VERSION ""

BU_: CH DIPF DIPR ETH FC HVI HVS PARTY SDCV VEH VIRT
BO_ 962 VCLEFT_switchStatus: 8 VEH
 SG_ VCLEFT_frontBuckleSwitch m0: 48|2@1+ (1,0) [0|3] "" gtw
 SG_ VCLEFT_btnWindowSwPackUpLF m0: 32|1@1+ (1,0) [0|1] "" gtw
 SG_ VCLEFT_frontSeatTrackBack m0: 8|2@1+ (1,0) [0|3] "" gtw
 SG_ VCLEFT_btnWindowSwPackAutoDownLF m0: 35|1@1+ (1,0) [0|1] "" gtw
 SG_ VCLEFT_btnWindowSwPackDownRR m0: 46|1@1+ (1,0) [0|1] "" gtw
 SG_ VCLEFT_btnWindowSwPackAutoUpRR m0: 45|1@1+ (1,0) [0|1] "" gtw
 SG_ VCLEFT_btnWindowSwPackAutoDownRR m0: 47|1@1+ (1,0) [0|1] "" gtw
 SG_ VCLEFT_rightMirrorTilt m0: 5|3@1+ (1,0) [0|4] "" vcright
 SG_ VCLEFT_btnWindowSwPackUpRR m0: 44|1@1+ (1,0) [0|1] "" gtw
 SG_ VCLEFT_frontOccupancySwitch m0: 50|2@1+ (1,0) [0|3] "" gtw
 SG_ VCLEFT_swcRightTiltLeft m1: 8|2@1+ (1,0) [0|3] "" das
 SG_ VCLEFT_rearRightOccupancySwitch m0: 58|2@1+ (1,0) [0|3] "" gtw
 SG_ VCLEFT_btnWindowSwPackDownLF m0: 34|1@1+ (1,0) [0|1] "" gtw
 SG_ VCLEFT_btnWindowSwPackAutoUpLF m0: 33|1@1+ (1,0) [0|1] "" gtw
 SG_ VCLEFT_swcLeftTiltRight m1: 3|2@1+ (1,0) [0|3] "" das
 SG_ VCLEFT_frontSeatBackrestForward m0: 22|2@1+ (1,0) [0|3] "" gtw
 SG_ VCLEFT_swcRightTiltRight m1: 10|2@1+ (1,0) [0|3] "" das
 SG_ VCLEFT_swcLeftScrollTicks m1: 16|6@1- (1,0) [-32|31] "" das
 SG_ VCLEFT_btnWindowUpLR m1: 32|1@1+ (1,0) [0|1] "" gtw
 SG_ VCLEFT_btnWindowAutoDownLR m1: 35|1@1+ (1,0) [0|1] "" gtw
 SG_ VCLEFT_btnWindowSwPackDownRF m0: 42|1@1+ (1,0) [0|1] "" gtw
 SG_ VCLEFT_btnWindowSwPackAutoUpRF m0: 41|1@1+ (1,0) [0|1] "" gtw
 SG_ VCLEFT_frontSeatLumbarIn m0: 28|2@1+ (1,0) [0|3] "" gtw
 SG_ VCLEFT_frontSeatLiftUp m0: 18|2@1+ (1,0) [0|3] "" gtw
 SG_ VCLEFT_btnWindowSwPackDownLR m0: 38|1@1+ (1,0) [0|1] "" gtw
 SG_ VCLEFT_btnWindowSwPackAutoUpLR m0: 37|1@1+ (1,0) [0|1] "" gtw
 SG_ VCLEFT_frontSeatLumbarDown m0: 24|2@1+ (1,0) [0|3] "" gtw
 SG_ VCLEFT_driverPresent m0: 4|1@1+ (1,0) [0|1] "" das
 SG_ VCLEFT_frontSeatTiltDown m0: 12|2@1+ (1,0) [0|3] "" gtw
 SG_ VCLEFT_frontSeatTrackForward m0: 10|2@1+ (1,0) [0|3] "" gtw
 SG_ VCLEFT_rearLeftBuckleSwitch m0: 52|2@1+ (1,0) [0|3] "" gtw
 SG_ VCLEFT_hazardButtonPressed m0: 3|1@1+ (1,0) [0|1] "" gtw
 SG_ VCLEFT_swcRightScrollTicks m1: 24|6@1- (1,0) [-32|31] "" das
 SG_ VCLEFT_swcRightPressed m1: 12|2@1+ (1,0) [0|3] "" das
 SG_ VCLEFT_frontSeatLumbarOut m0: 30|2@1+ (1,0) [0|3] "" gtw
 SG_ VCLEFT_brakePressed m0: 60|1@1+ (1,0) [0|1] "" di
 SG_ VCLEFT_swcLeftTiltLeft m1: 14|2@1+ (1,0) [0|3] "" das
 SG_ VCLEFT_swcLeftPressed m1: 5|2@1+ (1,0) [0|3] "" das
 SG_ VCLEFT_btnWindowSwPackUpLR m0: 36|1@1+ (1,0) [0|1] "" gtw
 SG_ VCLEFT_frontSeatTiltUp m0: 14|2@1+ (1,0) [0|3] "" gtw
 SG_ VCLEFT_rearLeftOccupancySwitch m0: 56|2@1+ (1,0) [0|3] "" gtw
 SG_ VCLEFT_frontSeatBackrestBack m0: 20|2@1+ (1,0) [0|3] "" gtw
 SG_ VCLEFT_btnWindowSwPackAutoDownLR m0: 39|1@1+ (1,0) [0|1] "" gtw
 SG_ VCLEFT_rearCenterOccupancySwitch m0: 54|2@1+ (1,0) [0|3] "" gtw
 SG_ VCLEFT_frontSeatLumbarUp m0: 26|2@1+ (1,0) [0|3] "" gtw
 SG_ VCLEFT_frontSeatLiftDown m0: 16|2@1+ (1,0) [0|3] "" gtw
 SG_ VCLEFT_hornSwitchPressed m0: 2|1@1+ (1,0) [0|1] "" app
 SG_ VCLEFT_btnWindowSwPackUpRF m0: 40|1@1+ (1,0) [0|1] "" gtw
 SG_ VCLEFT_btnWindowAutoUpLR m1: 33|1@1+ (1,0) [0|1] "" gtw
 SG_ VCLEFT_btnWindowSwPackAutoDownRF m0: 43|1@1+ (1,0) [0|1] "" gtw
 SG_ VCLEFT_switchStatusIndex M: 0|2@1+ (1,0) [0|2] "" X
 SG_ VCLEFT_btnWindowDownLR m1: 34|1@1+ (1,0) [0|1] "" gtw
 SG_ VCLEFT_rearHVACButtonPressed m0: 61|1@1+ (1,0) [0|1] "" gtw

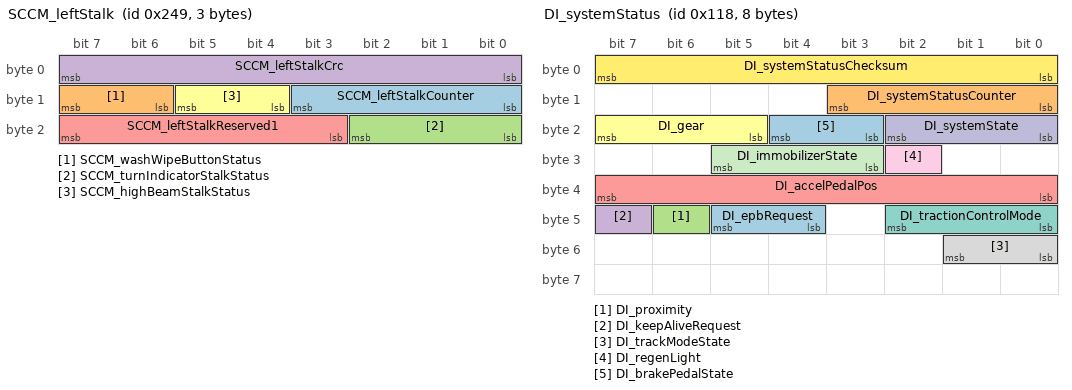
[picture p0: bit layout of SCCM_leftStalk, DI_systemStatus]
BO_ 585 SCCM_leftStalk: 3 VEH
 SG_ SCCM_leftStalkCounter : 8|4@1+ (1,0) [0|15] "" X
 SG_ SCCM_washWipeButtonStatus : 14|2@1+ (1,0) [0|3] "" das
 SG_ SCCM_turnIndicatorStalkStatus : 16|3@1+ (1,0) [0|5] "" das
 SG_ SCCM_leftStalkCrc : 0|8@1+ (1,0) [0|255] "" X
 SG_ SCCM_leftStalkReserved1 : 19|5@1+ (1,0) [0|31] "" X
 SG_ SCCM_highBeamStalkStatus : 12|2@1+ (1,0) [0|3] "" das

BO_ 280 DI_systemStatus: 8 VEH
 SG_ DI_epbRequest : 44|2@1+ (1,0) [0|2] "" epbl
 SG_ DI_systemStatusCounter : 8|4@1+ (1,0) [0|15] "" X
 SG_ DI_proximity : 46|1@1+ (1,0) [0|1] "" bms
 SG_ DI_keepAliveRequest : 47|1@1+ (1,0) [0|1] "" bms
 SG_ DI_accelPedalPos : 32|8@1+ (0.4,0) [0|100] "%" vcfront
 SG_ DI_gear : 21|3@1+ (1,0) [0|7] "" gtw
 SG_ DI_tractionControlMode : 40|3@1+ (1,0) [0|5] "" X
 SG_ DI_trackModeState : 48|2@1+ (1,0) [0|2] "" gtw
 SG_ DI_regenLight : 26|1@1+ (1,0) [0|1] "" vcleft
 SG_ DI_systemState : 16|3@1+ (1,0) [0|5] "" epbl
 SG_ DI_immobilizerState : 27|3@1+ (1,0) [0|6] "" X
 SG_ DI_systemStatusChecksum : 0|8@1+ (1,0) [0|255] "" X
 SG_ DI_brakePedalState : 19|2@1+ (1,0) [0|2] "" vcleft

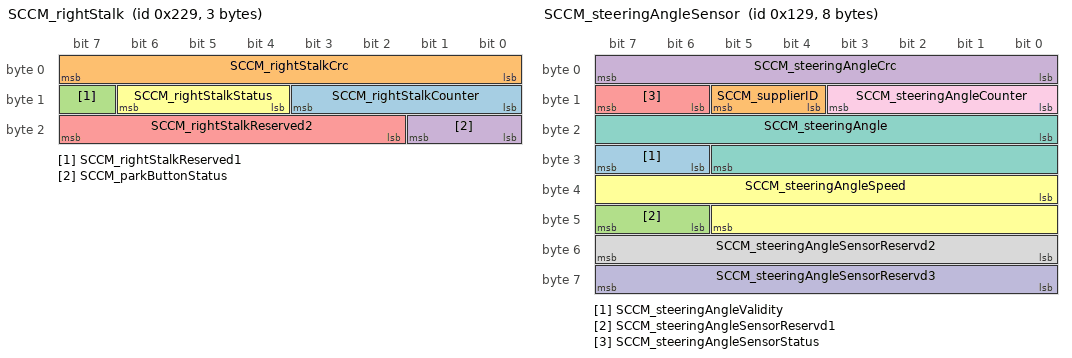
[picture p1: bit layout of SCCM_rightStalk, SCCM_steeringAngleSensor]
BO_ 553 SCCM_rightStalk: 3 VEH
 SG_ SCCM_rightStalkCounter : 8|4@1+ (1,0) [0|15] "" X
 SG_ SCCM_rightStalkCrc : 0|8@1+ (1,0) [0|255] "" X
 SG_ SCCM_rightStalkReserved1 : 15|1@1+ (1,0) [0|1] "" X
 SG_ SCCM_parkButtonStatus : 16|2@1+ (1,0) [0|3] "" das
 SG_ SCCM_rightStalkReserved2 : 18|6@1+ (1,0) [0|63] "" X
 SG_ SCCM_rightStalkStatus : 12|3@1+ (1,0) [0|6] "" das

BO_ 297 SCCM_steeringAngleSensor: 8 VEH
 SG_ SCCM_steeringAngleValidity : 30|2@1+ (1,0) [0|3] "" gtw
 SG_ SCCM_supplierID : 12|2@1+ (1,0) [0|3] "" gtw
 SG_ SCCM_steeringAngleSensorReservd1 : 46|2@1+ (1,0) [0|3] "" X
 SG_ SCCM_steeringAngleCrc : 0|8@1+ (1,0) [0|255] "" gtw
 SG_ SCCM_steeringAngleSensorStatus : 14|2@1+ (1,0) [0|3] "" aps
 SG_ SCCM_steeringAngleSpeed : 32|14@1+ (0.5,-4096) [-4096|4095.5] "deg/s" das
 SG_ SCCM_steeringAngle : 16|14@1+ (0.1,-819.2) [-819.2|819] "deg" aps
 SG_ SCCM_steeringAngleSensorReservd2 : 48|8@1+ (1,0) [0|255] "" X
 SG_ SCCM_steeringAngleCounter : 8|4@1+ (1,0) [0|15] "" gtw
 SG_ SCCM_steeringAngleSensorReservd3 : 56|8@1+ (1,0) [0|255] "" X

BO_ 568 STW_ACTN_RQ: 8 STW
 SG_ SpdCtrlLvr_Stat : 0|6@1+ (1,0) [0|0] "" NEO
 SG_ VSL_Enbl_Rq : 6|1@1+ (1,0) [0|0] "" NEO
 SG_ SpdCtrlLvrStat_Inv : 7|1@1+ (1,0) [0|0] "" NEO
 SG_ DTR_Dist_Rq : 8|8@1+ (1,0) [0|200] "" NEO
 SG_ TurnIndLvr_Stat : 16|2@1+ (1,0) [0|0] "" NEO
 SG_ HiBmLvr_Stat : 18|2@1+ (1,0) [0|0] "" NEO
 SG_ WprWashSw_Psd : 20|2@1+ (1,0) [0|0] "" NEO
 SG_ WprWash_R_Sw_Posn_V2 : 22|2@1+ (1,0) [0|0] "" NEO
 SG_ StW_Lvr_Stat : 24|3@1+ (1,0) [0|0] "" NEO
 SG_ StW_Cond_Flt : 27|1@1+ (1,0) [0|0] "" NEO
 SG_ StW_Cond_Psd : 28|2@1+ (1,0) [0|0] "" NEO
 SG_ HrnSw_Psd : 30|2@1+ (1,0) [0|0] "" NEO
 SG_ StW_Sw00_Psd : 32|1@1+ (1,0) [0|0] "" NEO
 SG_ StW_Sw01_Psd : 33|1@1+ (1,0) [0|0] "" NEO
 SG_ StW_Sw02_Psd : 34|1@1+ (1,0) [0|0] "" NEO
 SG_ StW_Sw03_Psd : 35|1@1+ (1,0) [0|0] "" NEO
 SG_ StW_Sw04_Psd : 36|1@1+ (1,0) [0|0] "" NEO
 SG_ StW_Sw05_Psd : 37|1@1+ (1,0) [0|0] "" NEO
 SG_ StW_Sw06_Psd : 38|1@1+ (1,0) [0|0] "" NEO
 SG_ StW_Sw07_Psd : 39|1@1+ (1,0) [0|0] "" NEO
 SG_ StW_Sw08_Psd : 40|1@1+ (1,0) [0|0] "" NEO
 SG_ StW_Sw09_Psd : 41|1@1+ (1,0) [0|0] "" NEO
 SG_ StW_Sw10_Psd : 42|1@1+ (1,0) [0|0] "" NEO
 SG_ StW_Sw11_Psd : 43|1@1+ (1,0) [0|0] "" NEO
 SG_ StW_Sw12_Psd : 44|1@1+ (1,0) [0|0] "" NEO
 SG_ StW_Sw13_Psd : 45|1@1+ (1,0) [0|0] "" NEO
 SG_ StW_Sw14_Psd : 46|1@1+ (1,0) [0|0] "" NEO
 SG_ StW_Sw15_Psd : 47|1@1+ (1,0) [0|0] "" NEO
 SG_ WprSw6Posn : 48|3@1+ (1,0) [0|0] "" NEO
 SG_ MC_STW_ACTN_RQ : 52|4@1+ (1,0) [0|15] "" NEO
 SG_ CRC_STW_ACTN_RQ : 56|8@1+ (1,0) [0|0] "" NEO

BO_ 737 VCFRONT_status: 8 VEH
 SG_ VCFRONT_statusIndex M : 0|3@1+ (1,0) [0|6] ""  Receiver
 SG_ VCFRONT_12VARailStable m5 : 5|1@1+ (1,0) [0|1] ""  Receiver
 SG_ VCFRONT_12VBRailStable m5 : 6|1@1+ (1,0) [0|1] ""  Receiver
 SG_ VCFRONT_12VOverchargeCounter m4 : 16|4@1+ (1,0) [0|15] ""  Receiver
 SG_ VCFRONT_5VARailStable m5 : 3|1@1+ (1,0) [0|1] ""  Receiver
 SG_ VCFRONT_5VBRailStable m5 : 4|1@1+ (1,0) [0|1] ""  Receiver
 SG_ VCFRONT_AS8510Voltage m5 : 28|12@1+ (0.00544368,0) [0|22.2864] "V"  Receiver
 SG_ VCFRONT_ChargePumpVoltageStable m5 : 9|1@1+ (1,0) [0|1] ""  Receiver
 SG_ VCFRONT_HSDInitCompleteU13 m5 : 11|1@1+ (1,0) [0|1] ""  Receiver
 SG_ VCFRONT_HSDInitCompleteU16 m5 : 12|1@1+ (1,0) [0|1] ""  Receiver
 SG_ VCFRONT_IBSFault m4 : 15|1@1+ (1,0) [0|1] ""  Receiver
 SG_ VCFRONT_PCSMia m4 : 14|1@1+ (1,0) [0|1] ""  Receiver
 SG_ VCFRONT_PEResetLineState m5 : 10|1@1+ (1,0) [0|1] ""  Receiver
 SG_ VCFRONT_airCompressorStatus m0 : 25|3@1+ (1,0) [0|7] ""  Receiver
 SG_ VCFRONT_anyClosureOpen m0 : 49|1@1+ (1,0) [0|1] ""  Receiver
 SG_ VCFRONT_anyDoorOpen m0 : 50|1@1+ (1,0) [0|1] ""  Receiver
 SG_ VCFRONT_batterySMState m1 : 16|4@1+ (1,0) [0|8] ""  Receiver
 SG_ VCFRONT_chargeNeeded m4 : 13|1@1+ (1,0) [0|1] ""  Receiver
 SG_ VCFRONT_chillerDemandActive m3 : 26|1@1+ (1,0) [0|1] ""  Receiver
 SG_ VCFRONT_compPerfRecoveryLimited m3 : 27|1@1+ (1,0) [0|1] ""  Receiver
 SG_ VCFRONT_coolantFillRoutineStatus m3 : 50|2@1+ (1,0) [0|3] ""  Receiver
 SG_ VCFRONT_crashDetectedType m0 : 20|2@1+ (1,0) [0|3] ""  Receiver
 SG_ VCFRONT_crashState m0 : 22|2@1+ (1,0) [0|3] ""  Receiver
 SG_ VCFRONT_crashUnlockOverrideSet m0 : 24|1@1+ (1,0) [0|1] ""  Receiver
 SG_ VCFRONT_epasWakeLine m1 : 4|1@1+ (1,0) [0|1] ""  Receiver
 SG_ VCFRONT_freezeEvapITerm m3 : 24|1@1+ (1,0) [0|1] ""  Receiver
 SG_ VCFRONT_frunkAccessPost m0 : 62|1@1+ (1,0) [0|1] ""  Receiver
 SG_ VCFRONT_frunkInteriorRelSwitch m0 : 48|1@1+ (1,0) [0|1] ""  Receiver
 SG_ VCFRONT_frunkLatchStatus m0 : 3|4@1+ (1,0) [0|8] ""  Receiver
 SG_ VCFRONT_frunkLatchType m0 : 58|2@1+ (1,0) [0|2] ""  Receiver
 SG_ VCFRONT_hasLowRefrigerant m3 : 29|1@1+ (1,0) [0|1] ""  Receiver
 SG_ VCFRONT_headlampLeftFanStatus m0 : 60|1@1+ (1,0) [0|1] ""  Receiver
 SG_ VCFRONT_headlampRightFanStatus m0 : 61|1@1+ (1,0) [0|1] ""  Receiver
 SG_ VCFRONT_headlightLeftVPosition m0 : 28|10@1+ (1,0) [0|1023] "ticks"  Receiver
 SG_ VCFRONT_headlightRightVPosition m0 : 38|10@1+ (1,0) [0|1023] "ticks"  Receiver
 SG_ VCFRONT_homelinkCommStatus m2 : 48|2@1+ (1,0) [0|3] ""  Receiver
 SG_ VCFRONT_homelinkV2Response0 m2 : 8|8@1+ (1,0) [0|255] ""  Receiver
 SG_ VCFRONT_homelinkV2Response1 m2 : 16|8@1+ (1,0) [0|255] ""  Receiver
 SG_ VCFRONT_homelinkV2Response2 m2 : 24|8@1+ (1,0) [0|255] ""  Receiver
 SG_ VCFRONT_homelinkV2Response3 m2 : 32|8@1+ (1,0) [0|255] ""  Receiver
 SG_ VCFRONT_homelinkV2Response4 m2 : 40|8@1+ (1,0) [0|255] ""  Receiver
 SG_ VCFRONT_hornOn m0 : 51|1@1+ (1,0) [0|1] ""  Receiver
 SG_ VCFRONT_hvacModeNotAttainable m3 : 28|1@1+ (1,0) [0|1] ""  Receiver
 SG_ VCFRONT_hvacPerfTestCommand m3 : 48|2@1+ (1,0) [0|3] ""  Receiver
 SG_ VCFRONT_iBoosterStateDBG m1 : 5|3@1+ (1,0) [0|4] ""  Receiver
 SG_ VCFRONT_iBoosterWakeLine m1 : 3|1@1+ (1,0) [0|1] ""  Receiver
 SG_ VCFRONT_isActiveHeatingBattery m0 : 63|1@1+ (1,0) [0|1] ""  Receiver
 SG_ VCFRONT_isColdStartRunning m3 : 30|1@1+ (1,0) [0|1] ""  Receiver
 SG_ VCFRONT_isEvapOperationAllowed m3 : 25|1@1+ (1,0) [0|1] ""  Receiver
 SG_ VCFRONT_isHeatPumpOilPurgeActive m3 : 31|1@1+ (1,0) [0|1] ""  Receiver
 SG_ VCFRONT_maxEvapHeatRejection m3 : 8|8@1+ (65,0) [0|16575] "W"  Receiver
 SG_ VCFRONT_minEvapHeatRejection m3 : 16|8@1+ (10,0) [0|2500] "W"  Receiver
 SG_ VCFRONT_passengerBuckleStatus m0 : 57|1@1+ (1,0) [0|1] ""  Receiver
 SG_ VCFRONT_pressureRefrigDischarge m3 : 40|8@1+ (0.125,0) [0|31.75] "bar"  Receiver
 SG_ VCFRONT_pressureRefrigSuction m3 : 32|7@1+ (0.125,0) [0|11.5] "bar"  Receiver
 SG_ VCFRONT_radarHeaterState m0 : 52|3@1+ (1,0) [0|4] ""  Receiver
 SG_ VCFRONT_railAState m5 : 7|1@1+ (1,0) [0|1] ""  Receiver
 SG_ VCFRONT_railBState m5 : 8|1@1+ (1,0) [0|1] ""  Receiver
 SG_ VCFRONT_refrigFillRoutineStatus m3 : 52|2@1+ (1,0) [0|3] ""  Receiver
 SG_ VCFRONT_reverseBatteryFault m4 : 30|1@1+ (1,0) [0|1] ""  Receiver
 SG_ VCFRONT_shortedCellFaultCounter m4 : 44|3@1+ (1,0) [0|7] ""  Receiver
 SG_ VCFRONT_silentWakeIBSCurrent m4 : 32|12@1- (0.1,-204.7) [-409.5|0] "mA"  Receiver
 SG_ VCFRONT_sleepCurrent m1 : 32|12@1- (0.1,-204.7) [-409.5|0] "mA"  Receiver
 SG_ VCFRONT_tempCompTargetVoltage m4 : 3|10@1+ (0.01,9) [9|16] "V"  Receiver
 SG_ VCFRONT_timeSpentSleeping m1 : 24|8@1+ (1,0) [0|255] "s"  Receiver
 SG_ VCFRONT_vbatMonitorVoltage m5 : 16|12@1+ (0.00544368,0) [0|22.2864] "V"  Receiver
 SG_ VCFRONT_vbatProt m5 : 40|12@1+ (0.00544368,0) [0|22.2919] "V"  Receiver
 SG_ VCFRONT_vehicleStatusDBG m1 : 8|5@1+ (1,0) [0|17] ""  Receiver
 SG_ VCFRONT_voltageDropCounter m4 : 20|4@1+ (1,0) [0|15] ""  Receiver
 SG_ VCFRONT_voltageFloorReachedCount m4 : 24|4@1+ (1,0) [0|15] ""  Receiver
 SG_ VCFRONT_voltageProfile m4 : 28|2@1+ (1,0) [0|3] ""  Receiver
 SG_ VCFRONT_wiperPosition m0 : 12|3@1+ (1,0) [0|4] ""  Receiver
 SG_ VCFRONT_wiperSpeed m0 : 8|4@1+ (1,0) [0|8] ""  Receiver
 SG_ VCFRONT_wiperState m0 : 16|4@1+ (1,0) [0|12] ""  Receiver

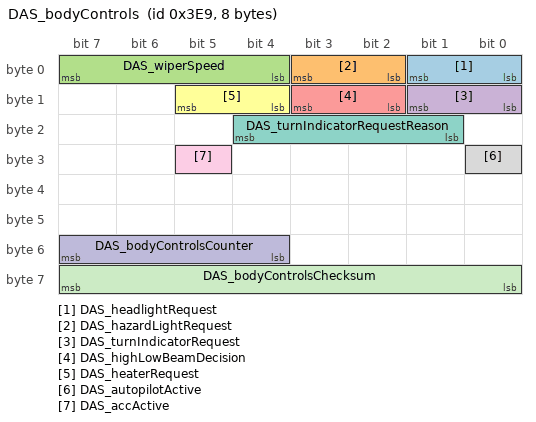
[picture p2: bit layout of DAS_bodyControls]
BO_ 1001 DAS_bodyControls: 8 VEH
 SG_ DAS_headlightRequest : 0|2@1+ (1,0) [0|3] "" aps
 SG_ DAS_hazardLightRequest : 2|2@1+ (1,0) [0|3] "" aps
 SG_ DAS_wiperSpeed : 4|4@1+ (1,0) [0|15] "" aps
 SG_ DAS_turnIndicatorRequest : 8|2@1+ (1,0) [0|3] "" aps
 SG_ DAS_highLowBeamDecision : 10|2@1+ (1,0) [0|3] "" aps
 SG_ DAS_heaterRequest : 12|2@1+ (1,0) [0|2] "" aps
 SG_ DAS_turnIndicatorRequestReason : 17|4@1+ (1,0) [0|8] "" aps
 SG_ DAS_autopilotActive : 24|1@1+ (1,0) [0|1] "" XXX
 SG_ DAS_accActive : 29|1@1+ (1,0) [0|1] "" XXX
 SG_ DAS_bodyControlsCounter : 52|4@1+ (1,0) [0|15] "" aps
 SG_ DAS_bodyControlsChecksum : 56|8@1+ (1,0) [0|255] "" aps

BO_ 1013 ID3F5VCFRONT_lighting: 8 VEH
 SG_ VCFRONT_lowBeamsCalibrated : 62|1@1+ (1,0) [0|1] ""  Receiver
 SG_ VCFRONT_lowBeamsOnForDRL : 61|1@1+ (1,0) [0|1] ""  Receiver
 SG_ VCFRONT_simLatchingStalk : 59|2@1+ (1,0) [0|3] ""  Receiver
 SG_ VCFRONT_highBeamSwitchActive : 58|1@1+ (1,0) [0|1] ""  Receiver
 SG_ VCFRONT_parkRightStatus : 56|2@1+ (1,0) [0|3] ""  Receiver
 SG_ VCFRONT_parkLeftStatus : 54|2@1+ (1,0) [0|3] ""  Receiver
 SG_ VCFRONT_turnSignalRightStatus : 52|2@1+ (1,0) [0|3] ""  Receiver
 SG_ VCFRONT_turnSignalLeftStatus : 50|2@1+ (1,0) [0|3] ""  Receiver
 SG_ VCFRONT_sideRepeaterRightStatus : 48|2@1+ (1,0) [0|3] ""  Receiver
 SG_ VCFRONT_sideRepeaterLeftStatus : 46|2@1+ (1,0) [0|3] ""  Receiver
 SG_ VCFRONT_sideMarkersStatus : 44|2@1+ (1,0) [0|3] ""  Receiver
 SG_ VCFRONT_fogRightStatus : 42|2@1+ (1,0) [0|3] ""  Receiver
 SG_ VCFRONT_fogLeftStatus : 40|2@1+ (1,0) [0|3] ""  Receiver
 SG_ VCFRONT_DRLRightStatus : 38|2@1+ (1,0) [0|3] ""  Receiver
 SG_ VCFRONT_DRLLeftStatus : 36|2@1+ (1,0) [0|3] ""  Receiver
 SG_ VCFRONT_highBeamRightStatus : 34|2@1+ (1,0) [0|3] ""  Receiver
 SG_ VCFRONT_highBeamLeftStatus : 32|2@1+ (1,0) [0|3] ""  Receiver
 SG_ VCFRONT_lowBeamRightStatus : 30|2@1+ (1,0) [0|3] ""  Receiver
 SG_ VCFRONT_lowBeamLeftStatus : 28|2@1+ (1,0) [0|3] ""  Receiver
 SG_ VCFRONT_hazardSwitchBacklight : 27|1@1+ (1,0) [0|1] ""  Receiver
 SG_ VCFRONT_seeYouHomeLightingReq : 26|1@1+ (1,0) [0|1] ""  Receiver
 SG_ VCFRONT_approachLightingRequest : 25|1@1+ (1,0) [0|1] ""  Receiver
 SG_ VCFRONT_courtesyLightingRequest : 24|1@1+ (1,0) [0|1] ""  Receiver
 SG_ VCFRONT_switchLightingBrightness : 16|8@1+ (0.5,0) [0|127] "%"  Receiver
 SG_ VCFRONT_ambientLightingBrightnes : 8|8@1+ (0.5,0) [0|127] "%"  Receiver
 SG_ VCFRONT_hazardLightRequest : 4|4@1+ (1,0) [0|8] ""  Receiver
 SG_ VCFRONT_indicatorRightRequest : 2|2@1+ (1,0) [0|2] ""  Receiver
 SG_ VCFRONT_indicatorLeftRequest : 0|2@1+ (1,0) [0|2] ""  Receiver

VAL_ 568 SpdCtrlLvr_Stat 32 "DN_1ST" 16 "UP_1ST" 8 "DN_2ND" 4 "UP_2ND" 2 "RWD" 1 "FWD" 0 "IDLE" ;
VAL_ 568 DTR_Dist_Rq 255 "SNA" 200 "ACC_DIST_7" 166 "ACC_DIST_6" 133 "ACC_DIST_5" 100 "ACC_DIST_4" 66 "ACC_DIST_3" 33 "ACC_DIST_2" 0 "ACC_DIST_1" ;
VAL_ 568 TurnIndLvr_Stat 3 "SNA" 2 "RIGHT" 1 "LEFT" 0 "IDLE" ;
VAL_ 568 HiBmLvr_Stat 3 "SNA" 2 "HIBM_FLSH_ON_PSD" 1 "HIBM_ON_PSD" 0 "IDLE" ;
VAL_ 568 WprWashSw_Psd 3 "SNA" 2 "WASH" 1 "TIPWIPE" 0 "NPSD" ;
VAL_ 568 WprWash_R_Sw_Posn_V2 3 "SNA" 2 "WASH" 1 "INTERVAL" 0 "OFF" ;
VAL_ 568 StW_Lvr_Stat 4 "STW_BACK" 3 "STW_FWD" 2 "STW_DOWN" 1 "STW_UP" 0 "NPSD" ;
VAL_ 568 StW_Cond_Psd 3 "SNA" 2 "DOWN" 1 "UP" 0 "NPSD" ;
VAL_ 568 HrnSw_Psd 3 "SNA" 2 "NDEF2" 1 "PSD" 0 "NPSD" ;
VAL_ 568 StW_Sw00_Psd 1 "PRESSED" 0 "NOT_PRESSED_SNA" ;
VAL_ 568 StW_Sw01_Psd 1 "PRESSED" 0 "NOT_PRESSED_SNA" ;
VAL_ 568 StW_Sw03_Psd 1 "PRESSED" 0 "NOT_PRESSED_SNA" ;
VAL_ 568 StW_Sw04_Psd 1 "PRESSED" 0 "NOT_PRESSED_SNA" ;
VAL_ 568 WprSw6Posn 7 "SNA" 6 "STAGE2" 5 "STAGE1" 4 "INTERVAL4" 3 "INTERVAL3" 2 "INTERVAL2" 1 "INTERVAL1" 0 "OFF" ;

VAL_ 737 VCFRONT_statusIndex 0 "VCF_STS_IDX_BODY_CONTROLS" 2 "VCF_STS_IDX_HOMELINK" 6 "VCF_STS_IDX_INVALID" 4 "VCF_STS_IDX_LV_BATTERY" 3 "VCF_STS_IDX_REFRIGERANT_SYSTEM" 5 "VCF_STS_IDX_SYSTEM_HEALTH" 1 "VCF_STS_IDX_VEHICLE_STATE" ;
VAL_ 737 VCFRONT_AS8510Voltage 4095 "SNA" ;
VAL_ 737 VCFRONT_airCompressorStatus 4 "VCFRONT_AIR_COMPRESSOR_STATUS_FAULT" 0 "VCFRONT_AIR_COMPRESSOR_STATUS_OFF" 1 "VCFRONT_AIR_COMPRESSOR_STATUS_ON" 5 "VCFRONT_AIR_COMPRESSOR_STATUS_RETRY_AVAILABLE" 7 "VCFRONT_AIR_COMPRESSOR_STATUS_SNA" 2 "VCFRONT_AIR_COMPRESSOR_STATUS_TURNING_OFF" 3 "VCFRONT_AIR_COMPRESSOR_STATUS_TURNING_ON" ;
VAL_ 737 VCFRONT_batterySMState 1 "BATTERY_SM_STATE_CHARGE" 2 "BATTERY_SM_STATE_DISCHARGE" 6 "BATTERY_SM_STATE_DISCONNECTED_BATTERY_TEST" 8 "BATTERY_SM_STATE_FAULT" 0 "BATTERY_SM_STATE_INIT" 5 "BATTERY_SM_STATE_OTA_STANDBY" 4 "BATTERY_SM_STATE_RESISTANCE_ESTIMATION" 7 "BATTERY_SM_STATE_SHORTED_CELL_TEST" 3 "BATTERY_SM_STATE_STANDBY" ;
VAL_ 737 VCFRONT_coolantFillRoutineStatus 3 "FAULTED" 1 "MOVING_TO_FILL_POSITION" 0 "NOT_READY" 2 "READY_TO_FILL" ;
VAL_ 737 VCFRONT_crashDetectedType 1 "CRASH_DETECTED_TYPE_MINOR_1" 2 "CRASH_DETECTED_TYPE_MINOR_2" 0 "CRASH_DETECTED_TYPE_NONE" 3 "CRASH_DETECTED_TYPE_SEVERE" ;
VAL_ 737 VCFRONT_crashState 0 "CRASH_STATE_IDLE" 1 "CRASH_STATE_MINOR_1" 2 "CRASH_STATE_MINOR_2" 3 "CRASH_STATE_SEVERE" ;
VAL_ 737 VCFRONT_frunkLatchStatus 5 "LATCH_AJAR" 2 "LATCH_CLOSED" 3 "LATCH_CLOSING" 7 "LATCH_DEFAULT" 8 "LATCH_FAULT" 1 "LATCH_OPENED" 4 "LATCH_OPENING" 0 "LATCH_SNA" 6 "LATCH_TIMEOUT" ;
VAL_ 737 VCFRONT_frunkLatchType 1 "FRUNK_LATCH_TYPE_DOUBLE_ACTUATOR" 2 "FRUNK_LATCH_TYPE_DOUBLE_PULL" 0 "FRUNK_LATCH_TYPE_UNKNOWN" ;
VAL_ 737 VCFRONT_homelinkCommStatus 3 "HOMELINK_COMM_STATUS_FAULT" 1 "HOMELINK_COMM_STATUS_OFF" 2 "HOMELINK_COMM_STATUS_ON" 0 "HOMELINK_COMM_STATUS_SNA" ;
VAL_ 737 VCFRONT_hvacPerfTestCommand 2 "BLOW" 1 "INIT" 0 "NOT_STARTED" 3 "STOP" ;
VAL_ 737 VCFRONT_iBoosterStateDBG 4 "IBOOSTER_FORCE_OFF" 2 "IBOOSTER_GOING_DOWN" 0 "IBOOSTER_OFF" 1 "IBOOSTER_ON" 3 "IBOOSTER_WRITING_DATA_SHUTDOWN" ;
VAL_ 737 VCFRONT_passengerBuckleStatus 1 "BUCKLED" 0 "UNBUCKLED" ;
VAL_ 737 VCFRONT_pressureRefrigDischarge 255 "SNA" ;
VAL_ 737 VCFRONT_pressureRefrigSuction 127 "SNA" ;
VAL_ 737 VCFRONT_radarHeaterState 4 "HEATER_STATE_FAULT" 2 "HEATER_STATE_OFF" 3 "HEATER_STATE_OFF_UNAVAILABLE" 1 "HEATER_STATE_ON" 0 "HEATER_STATE_SNA" ;
VAL_ 737 VCFRONT_refrigFillRoutineStatus 3 "FAULTED" 1 "MOVING_TO_FILL_POSITION" 0 "NOT_READY" 2 "READY_TO_FILL" ;
VAL_ 737 VCFRONT_vbatMonitorVoltage 4095 "SNA" ;
VAL_ 737 VCFRONT_vehicleStatusDBG 10 "VEHICLE_STATUS_ACCESSORY" 11 "VEHICLE_STATUS_ACCESSORY_PLUS" 3 "VEHICLE_STATUS_BATTERY_POST_WAKE" 12 "VEHICLE_STATUS_CONDITIONING" 14 "VEHICLE_STATUS_CRASH" 13 "VEHICLE_STATUS_DRIVE" 9 "VEHICLE_STATUS_HV_UP_STANDBY" 0 "VEHICLE_STATUS_INIT" 1 "VEHICLE_STATUS_LOW_POWER_STANDBY" 8 "VEHICLE_STATUS_LV_AWAKE" 7 "VEHICLE_STATUS_LV_SHUTDOWN" 15 "VEHICLE_STATUS_OTA" 17 "VEHICLE_STATUS_RESET" 2 "VEHICLE_STATUS_SILENT_WAKE" 5 "VEHICLE_STATUS_SLEEP_SHUTDOWN" 6 "VEHICLE_STATUS_SLEEP_STANDBY" 4 "VEHICLE_STATUS_SYSTEM_CHECKS" 16 "VEHICLE_STATUS_TURN_ON_RAILS" ;
VAL_ 737 VCFRONT_voltageProfile 3 "VOLTAGE_PROFILE_ALWAYS_CLOSED_CONTACTORS" 0 "VOLTAGE_PROFILE_CHARGE" 1 "VOLTAGE_PROFILE_FLOAT" 2 "VOLTAGE_PROFILE_REDUCED_FLOAT" ;
VAL_ 737 VCFRONT_wiperPosition 3 "WIPER_POSITION_DELAYED_REST" 2 "WIPER_POSITION_DEPRESSED_PARK" 1 "WIPER_POSITION_SERVICE" 0 "WIPER_POSITION_SNA" 4 "WIPER_POSITION_WIPING" ;
VAL_ 737 VCFRONT_wiperSpeed 2 "WIPER_SPEED_1" 3 "WIPER_SPEED_2" 4 "WIPER_SPEED_3" 5 "WIPER_SPEED_4" 6 "WIPER_SPEED_5" 8 "WIPER_SPEED_HIGH" 7 "WIPER_SPEED_LOW" 1 "WIPER_SPEED_OFF" 0 "WIPER_SPEED_SNA" ;
VAL_ 737 VCFRONT_wiperState 9 "WIPER_STATE_CONT_FAST" 10 "WIPER_STATE_CONT_SLOW" 3 "WIPER_STATE_DELAYED_REST" 2 "WIPER_STATE_FAULT" 7 "WIPER_STATE_INTERMITTENT_HIGH" 8 "WIPER_STATE_INTERMITTENT_LOW" 12 "WIPER_STATE_INT_AUTO_HIGH" 11 "WIPER_STATE_INT_AUTO_LOW" 6 "WIPER_STATE_MOMENTARY_WIPE" 4 "WIPER_STATE_PARK" 1 "WIPER_STATE_SERVICE" 0 "WIPER_STATE_SNA" 5 "WIPER_STATE_WASH" ;

VAL_ 1001 DAS_headlightRequest 3 "DAS_HEADLIGHT_REQUEST_INVALID" 1 "DAS_HEADLIGHT_REQUEST_ON" 0 "DAS_HEADLIGHT_REQUEST_OFF";
VAL_ 1001 DAS_hazardLightRequest 3 "DAS_REQUEST_HAZARDS_SNA" 2 "DAS_REQUEST_HAZARDS_UNUSED" 0 "DAS_REQUEST_HAZARDS_OFF" 1 "DAS_REQUEST_HAZARDS_ON";
VAL_ 1001 DAS_wiperSpeed 3 "DAS_WIPER_SPEED_3" 12 "DAS_WIPER_SPEED_12" 8 "DAS_WIPER_SPEED_8" 14 "DAS_WIPER_SPEED_14" 5 "DAS_WIPER_SPEED_5" 13 "DAS_WIPER_SPEED_13" 2 "DAS_WIPER_SPEED_2" 0 "DAS_WIPER_SPEED_OFF" 4 "DAS_WIPER_SPEED_4" 1 "DAS_WIPER_SPEED_1" 15 "DAS_WIPER_SPEED_INVALID" 10 "DAS_WIPER_SPEED_10" 11 "DAS_WIPER_SPEED_11" 7 "DAS_WIPER_SPEED_7" 9 "DAS_WIPER_SPEED_9" 6 "DAS_WIPER_SPEED_6";
VAL_ 1001 DAS_turnIndicatorRequest 0 "DAS_TURN_INDICATOR_NONE" 2 "DAS_TURN_INDICATOR_RIGHT" 3 "DAS_TURN_INDICATOR_CANCEL" 1 "DAS_TURN_INDICATOR_LEFT";
VAL_ 1001 DAS_highLowBeamDecision 2 "DAS_HIGH_BEAM_ON" 1 "DAS_HIGH_BEAM_OFF" 3 "DAS_HIGH_BEAM_SNA" 0 "DAS_HIGH_BEAM_UNDECIDED";
VAL_ 1001 DAS_heaterRequest 0 "DAS_HEATER_SNA" 2 "DAS_HEATER_ON" 1 "DAS_HEATER_OFF";
VAL_ 1001 DAS_turnIndicatorRequestReason 8 "DAS_ACTIVE_COMMANDED_LANE_CHANGE" 4 "DAS_CANCEL_LANE_CHANGE" 6 "DAS_ACTIVE_MERGE" 2 "DAS_ACTIVE_SPEED_LANE_CHANGE" 5 "DAS_CANCEL_FORK" 0 "DAS_NONE" 3 "DAS_ACTIVE_FORK" 7 "DAS_CANCEL_MERGE" 1 "DAS_ACTIVE_NAV_LANE_CHANGE";

VAL_ 1013 VCFRONT_DRLLeftStatus 2 "LIGHT_FAULT" 0 "LIGHT_OFF" 1 "LIGHT_ON" 3 "LIGHT_SNA" ;
VAL_ 1013 VCFRONT_DRLRightStatus 2 "LIGHT_FAULT" 0 "LIGHT_OFF" 1 "LIGHT_ON" 3 "LIGHT_SNA" ;
VAL_ 1013 VCFRONT_ambientLightingBrightnes 255 "SNA" ;
VAL_ 1013 VCFRONT_fogLeftStatus 2 "LIGHT_FAULT" 0 "LIGHT_OFF" 1 "LIGHT_ON" 3 "LIGHT_SNA" ;
VAL_ 1013 VCFRONT_fogRightStatus 2 "LIGHT_FAULT" 0 "LIGHT_OFF" 1 "LIGHT_ON" 3 "LIGHT_SNA" ;
VAL_ 1013 VCFRONT_hazardLightRequest 1 "HAZARD_REQUEST_BUTTON" 6 "HAZARD_REQUEST_CAR_ALARM" 5 "HAZARD_REQUEST_CRASH" 7 "HAZARD_REQUEST_DAS" 2 "HAZARD_REQUEST_LOCK" 4 "HAZARD_REQUEST_MISLOCK" 0 "HAZARD_REQUEST_NONE" 8 "HAZARD_REQUEST_UDS" 3 "HAZARD_REQUEST_UNLOCK" ;
VAL_ 1013 VCFRONT_highBeamLeftStatus 2 "LIGHT_FAULT" 0 "LIGHT_OFF" 1 "LIGHT_ON" 3 "LIGHT_SNA" ;
VAL_ 1013 VCFRONT_highBeamRightStatus 2 "LIGHT_FAULT" 0 "LIGHT_OFF" 1 "LIGHT_ON" 3 "LIGHT_SNA" ;
VAL_ 1013 VCFRONT_indicatorLeftRequest 2 "TURN_SIGNAL_ACTIVE_HIGH" 1 "TURN_SIGNAL_ACTIVE_LOW" 0 "TURN_SIGNAL_OFF" ;
VAL_ 1013 VCFRONT_indicatorRightRequest 2 "TURN_SIGNAL_ACTIVE_HIGH" 1 "TURN_SIGNAL_ACTIVE_LOW" 0 "TURN_SIGNAL_OFF" ;
VAL_ 1013 VCFRONT_lowBeamLeftStatus 2 "LIGHT_FAULT" 0 "LIGHT_OFF" 1 "LIGHT_ON" 3 "LIGHT_SNA" ;
VAL_ 1013 VCFRONT_lowBeamRightStatus 2 "LIGHT_FAULT" 0 "LIGHT_OFF" 1 "LIGHT_ON" 3 "LIGHT_SNA" ;
VAL_ 1013 VCFRONT_parkLeftStatus 2 "LIGHT_FAULT" 0 "LIGHT_OFF" 1 "LIGHT_ON" 3 "LIGHT_SNA" ;
VAL_ 1013 VCFRONT_parkRightStatus 2 "LIGHT_FAULT" 0 "LIGHT_OFF" 1 "LIGHT_ON" 3 "LIGHT_SNA" ;
VAL_ 1013 VCFRONT_sideMarkersStatus 2 "LIGHT_FAULT" 0 "LIGHT_OFF" 1 "LIGHT_ON" 3 "LIGHT_SNA" ;
VAL_ 1013 VCFRONT_sideRepeaterLeftStatus 2 "LIGHT_FAULT" 0 "LIGHT_OFF" 1 "LIGHT_ON" 3 "LIGHT_SNA" ;
VAL_ 1013 VCFRONT_sideRepeaterRightStatus 2 "LIGHT_FAULT" 0 "LIGHT_OFF" 1 "LIGHT_ON" 3 "LIGHT_SNA" ;
VAL_ 1013 VCFRONT_simLatchingStalk 0 "SIMULATED_LATCHING_STALK_IDLE" 1 "SIMULATED_LATCHING_STALK_LEFT" 2 "SIMULATED_LATCHING_STALK_RIGHT" 3 "SIMULATED_LATCHING_STALK_SNA" ;
VAL_ 1013 VCFRONT_switchLightingBrightness 255 "SNA" ;
VAL_ 1013 VCFRONT_turnSignalLeftStatus 2 "LIGHT_FAULT" 0 "LIGHT_OFF" 1 "LIGHT_ON" 3 "LIGHT_SNA" ;
VAL_ 1013 VCFRONT_turnSignalRightStatus 2 "LIGHT_FAULT" 0 "LIGHT_OFF" 1 "LIGHT_ON" 3 "LIGHT_SNA" ;
VAL_ 962 VCLEFT_frontBuckleSwitch 2 "SWITCH_ON" 0 "SWITCH_SNA" 3 "SWITCH_FAULT" 1 "SWITCH_OFF";
VAL_ 962 VCLEFT_frontSeatTrackBack 2 "SWITCH_ON" 0 "SWITCH_SNA" 3 "SWITCH_FAULT" 1 "SWITCH_OFF";
VAL_ 962 VCLEFT_rightMirrorTilt 4 "MIRROR_TILT_LEFT" 2 "MIRROR_TILT_UP" 3 "MIRROR_TILT_RIGHT" 0 "MIRROR_TILT_STOP" 1 "MIRROR_TILT_DOWN";
VAL_ 962 VCLEFT_frontOccupancySwitch 2 "SWITCH_ON" 0 "SWITCH_SNA" 3 "SWITCH_FAULT" 1 "SWITCH_OFF";
VAL_ 962 VCLEFT_swcRightTiltLeft 2 "SWITCH_ON" 0 "SWITCH_SNA" 3 "SWITCH_FAULT" 1 "SWITCH_OFF";
VAL_ 962 VCLEFT_rearRightOccupancySwitch 2 "SWITCH_ON" 0 "SWITCH_SNA" 3 "SWITCH_FAULT" 1 "SWITCH_OFF";
VAL_ 962 VCLEFT_swcLeftTiltRight 2 "SWITCH_ON" 0 "SWITCH_SNA" 3 "SWITCH_FAULT" 1 "SWITCH_OFF";
VAL_ 962 VCLEFT_frontSeatBackrestForward 2 "SWITCH_ON" 0 "SWITCH_SNA" 3 "SWITCH_FAULT" 1 "SWITCH_OFF";
VAL_ 962 VCLEFT_swcRightTiltRight 2 "SWITCH_ON" 0 "SWITCH_SNA" 3 "SWITCH_FAULT" 1 "SWITCH_OFF";
VAL_ 962 VCLEFT_frontSeatLumbarIn 2 "SWITCH_ON" 0 "SWITCH_SNA" 3 "SWITCH_FAULT" 1 "SWITCH_OFF";
VAL_ 962 VCLEFT_frontSeatLiftUp 2 "SWITCH_ON" 0 "SWITCH_SNA" 3 "SWITCH_FAULT" 1 "SWITCH_OFF";
VAL_ 962 VCLEFT_frontSeatLumbarDown 2 "SWITCH_ON" 0 "SWITCH_SNA" 3 "SWITCH_FAULT" 1 "SWITCH_OFF";
VAL_ 962 VCLEFT_frontSeatTiltDown 2 "SWITCH_ON" 0 "SWITCH_SNA" 3 "SWITCH_FAULT" 1 "SWITCH_OFF";
VAL_ 962 VCLEFT_frontSeatTrackForward 2 "SWITCH_ON" 0 "SWITCH_SNA" 3 "SWITCH_FAULT" 1 "SWITCH_OFF";
VAL_ 962 VCLEFT_rearLeftBuckleSwitch 2 "SWITCH_ON" 0 "SWITCH_SNA" 3 "SWITCH_FAULT" 1 "SWITCH_OFF";
VAL_ 962 VCLEFT_swcRightPressed 2 "SWITCH_ON" 0 "SWITCH_SNA" 3 "SWITCH_FAULT" 1 "SWITCH_OFF";
VAL_ 962 VCLEFT_frontSeatLumbarOut 2 "SWITCH_ON" 0 "SWITCH_SNA" 3 "SWITCH_FAULT" 1 "SWITCH_OFF";
VAL_ 962 VCLEFT_swcLeftTiltLeft 2 "SWITCH_ON" 0 "SWITCH_SNA" 3 "SWITCH_FAULT" 1 "SWITCH_OFF";
VAL_ 962 VCLEFT_swcLeftPressed 2 "SWITCH_ON" 0 "SWITCH_SNA" 3 "SWITCH_FAULT" 1 "SWITCH_OFF";
VAL_ 962 VCLEFT_frontSeatTiltUp 2 "SWITCH_ON" 0 "SWITCH_SNA" 3 "SWITCH_FAULT" 1 "SWITCH_OFF";
VAL_ 962 VCLEFT_rearLeftOccupancySwitch 2 "SWITCH_ON" 0 "SWITCH_SNA" 3 "SWITCH_FAULT" 1 "SWITCH_OFF";
VAL_ 962 VCLEFT_frontSeatBackrestBack 2 "SWITCH_ON" 0 "SWITCH_SNA" 3 "SWITCH_FAULT" 1 "SWITCH_OFF";
VAL_ 962 VCLEFT_rearCenterOccupancySwitch 2 "SWITCH_ON" 0 "SWITCH_SNA" 3 "SWITCH_FAULT" 1 "SWITCH_OFF";
VAL_ 962 VCLEFT_frontSeatLumbarUp 2 "SWITCH_ON" 0 "SWITCH_SNA" 3 "SWITCH_FAULT" 1 "SWITCH_OFF";
VAL_ 962 VCLEFT_frontSeatLiftDown 2 "SWITCH_ON" 0 "SWITCH_SNA" 3 "SWITCH_FAULT" 1 "SWITCH_OFF";
VAL_ 962 VCLEFT_switchStatusIndex 1 "VCLEFT_SWITCH_STATUS_INDEX_1" 2 "VCLEFT_SWITCH_STATUS_INDEX_INVALID" 0 "VCLEFT_SWITCH_STATUS_INDEX_0";
VAL_ 585 SCCM_washWipeButtonStatus 3 "SNA" 0 "NOT_PRESSED" 2 "2ND_DETENT" 1 "1ST_DETENT";
VAL_ 585 SCCM_turnIndicatorStalkStatus 3 "DOWN_1" 5 "SNA" 0 "IDLE" 1 "UP_1" 4 "DOWN_2" 2 "UP_2";
VAL_ 585 SCCM_highBeamStalkStatus 3 "SNA" 0 "IDLE" 1 "PULL" 2 "PUSH";
VAL_ 280 DI_epbRequest 0 "DI_EPBREQUEST_NO_REQUEST" 1 "DI_EPBREQUEST_PARK" 2 "DI_EPBREQUEST_UNPARK";
VAL_ 280 DI_keepAliveRequest 1 "KEEP_ALIVE" 0 "NO_REQUEST";
VAL_ 280 DI_accelPedalPos 255 "SNA";
VAL_ 280 DI_gear 1 "DI_GEAR_P" 0 "DI_GEAR_INVALID" 7 "DI_GEAR_SNA" 2 "DI_GEAR_R" 3 "DI_GEAR_N" 4 "DI_GEAR_D";
VAL_ 280 DI_tractionControlMode 0 "TC_NORMAL" 1 "TC_SLIP_START" 4 "TC_ROLLS_MODE" 2 "TC_DEV_MODE_1" 5 "TC_DYNO_MODE" 3 "TC_DEV_MODE_2";
VAL_ 280 DI_trackModeState 0 "TRACK_MODE_UNAVAILABLE" 1 "TRACK_MODE_AVAILABLE" 2 "TRACK_MODE_ON";
VAL_ 280 DI_systemState 5 "DI_SYS_ENABLE" 1 "DI_SYS_IDLE" 2 "DI_SYS_STANDBY" 0 "DI_SYS_UNAVAILABLE" 3 "DI_SYS_FAULT" 4 "DI_SYS_ABORT";
VAL_ 280 DI_immobilizerState 2 "DI_IMM_STATE_AUTHENTICATING" 0 "DI_IMM_STATE_INIT_SNA" 3 "DI_IMM_STATE_DISARMED" 4 "DI_IMM_STATE_IDLE" 6 "DI_IMM_STATE_FAULT" 1 "DI_IMM_STATE_REQUEST" 5 "DI_IMM_STATE_RESET";
VAL_ 280 DI_brakePedalState 2 "INVALID" 0 "OFF" 1 "ON";
VAL_ 553 SCCM_parkButtonStatus 3 "SNA" 0 "NOT_PRESSED" 2 "INIT" 1 "PRESSED";
VAL_ 553 SCCM_rightStalkStatus 3 "DOWN_1" 6 "SNA" 0 "IDLE" 5 "INIT" 1 "UP_1" 4 "DOWN_2" 2 "UP_2";
VAL_ 297 SCCM_steeringAngleValidity 3 "SNA" 2 "INIT" 0 "INVALID" 1 "VALID";
VAL_ 297 SCCM_steeringAngleSensorStatus 0 "OK" 1 "INIT" 2 "ERROR" 3 "ERROR_INIT";
